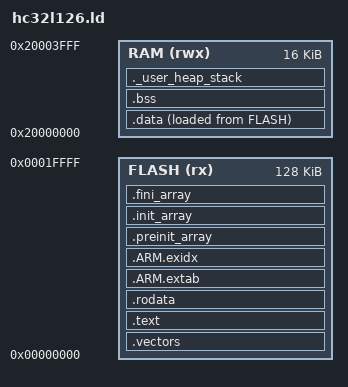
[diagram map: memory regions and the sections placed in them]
/******************************************************************************
 * Copyright (C) 2022-2025, Xiaohua Semiconductor Co., Ltd. All rights reserved.
 *
 * This software component is licensed by XHSC under BSD 3-Clause license
 * (the "License"); You may not use this file except in compliance with the
 * License. You may obtain a copy of the License at:
 *                    opensource.org/licenses/BSD-3-Clause
 *
 */
/*****************************************************************************/
/*  File        HC32F126xA.ld                                                */
/*  Abstract    Linker script for HC32F126xA Device with                     */
/*              128KByte FLASH, 16KByte RAM                                  */
/*  Version     V1.0                                                         */
/*  Date        2025-11-30                                                   */
/*****************************************************************************/

/* Highest address of the user mode stack */
_estack = 0x20004000;    /* end of RAM */

/* Generate a link error if heap and stack don't fit into RAM */
_Min_Heap_Size = 0x200;      /* required amount of heap  */
_Min_Stack_Size = 0x800; /* required amount of stack */

/* Use contiguous memory regions for simple. */
MEMORY
{
    FLASH  (rx): ORIGIN = 0x00000000, LENGTH = 128K
    RAM   (rwx): ORIGIN = 0x20000000, LENGTH = 16K
}

ENTRY(Reset_Handler)

SECTIONS
{
    /* 中断向量表 */
    .vectors :
    {
        . = ALIGN(4);
        KEEP(*(.vectors))
        . = ALIGN(4);
    } >FLASH

    /* 代码段 */
    .text :
    {
        . = ALIGN(4);
        *(.text)
        *(.text*)
        *(.glue_7)
        *(.glue_7t)
        *(.eh_frame)

        KEEP(*(.init))
        KEEP(*(.fini))
        . = ALIGN(4);
    } >FLASH

    .rodata :
    {
        . = ALIGN(4);
        *(.rodata)
        *(.rodata*)
        . = ALIGN(4);
    } >FLASH

    /* ARM异常处理段 */
    .ARM.extab :
    {
        *(.ARM.extab* .gnu.linkonce.armextab.*)
    } >FLASH

    __exidx_start = .;
    .ARM.exidx :
    {
        *(.ARM.exidx* .gnu.linkonce.armexidx.*)
    } >FLASH
    __exidx_end = .;

    /* 预初始化数组 */
    .preinit_array :
    {
        . = ALIGN(4);
        /* preinit data */
        PROVIDE_HIDDEN (__preinit_array_start = .);
        KEEP(*(.preinit_array))
        PROVIDE_HIDDEN (__preinit_array_end = .);
        . = ALIGN(4);
    } >FLASH

    /* 初始化数组 */
    .init_array :
    {
        . = ALIGN(4);
        /* init data */
        PROVIDE_HIDDEN (__init_array_start = .);
        KEEP(*(SORT(.init_array.*)))
        KEEP(*(.init_array))
        PROVIDE_HIDDEN (__init_array_end = .);
        . = ALIGN(4);
    } >FLASH

    /* 终止数组 */
    .fini_array :
    {
        . = ALIGN(4);
        /* finit data */
        PROVIDE_HIDDEN (__fini_array_start = .);
        KEEP(*(SORT(.fini_array.*)))
        KEEP(*(.fini_array))
        PROVIDE_HIDDEN (__fini_array_end = .);
        . = ALIGN(4);
    } >FLASH
	

    /* 数据段 (初始化的全局/静态变量/ramfunc) */
    __etext = LOADADDR(.data);
    .data :
    {
        . = ALIGN(4);
        __data_start__ = .;
        *(vtable)
        *(.data)
        *(.data*)
        . = ALIGN(4);
        *(.ramfunc)
        *(.ramfunc*)
        . = ALIGN(4);
        __data_end__ = .;
    } >RAM AT> FLASH

    /* 未初始化数据段 (BSS段) */
    .bss :
    {
        . = ALIGN(4);
        __bss_start__ = .;
        *(.bss*)
        *(COMMON)
        . = ALIGN(4);
        __bss_end__ = .;
    } >RAM

    /* 堆 栈空间 */
    /* User_heap_stack section, used to check that there is enough RAM left */
    ._user_heap_stack :
    {
      . = ALIGN(8);
      PROVIDE ( end = . );
      PROVIDE ( _end = . );
      . = . + _Min_Heap_Size;
      . = . + _Min_Stack_Size;
      . = ALIGN(8);
    } >RAM
    __StackTop = .;
    PROVIDE(_stack = __StackTop);

    ASSERT(__StackTop < _estack, "region RAM overflowed with stack")
}

